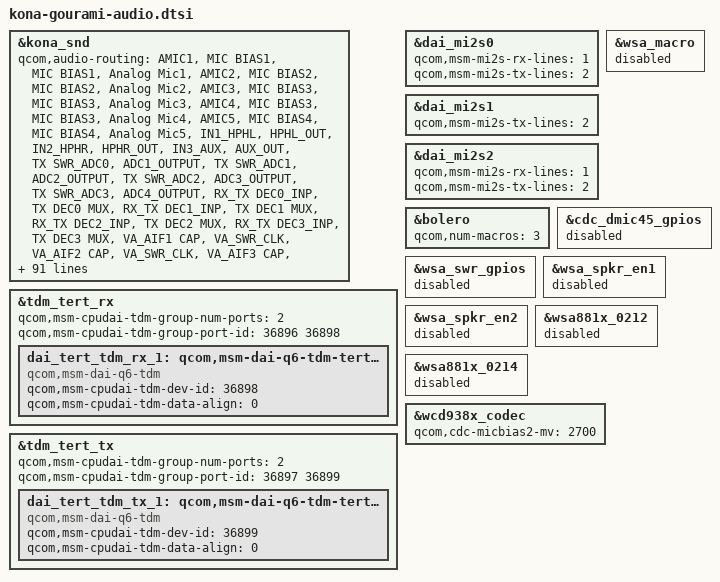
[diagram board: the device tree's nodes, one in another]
// SPDX-License-Identifier: GPL-2.0
/* Copyright (c) 2022, The Linux Foundation. All rights reserved.
 *
 * This program is free software; you can redistribute it and/or modify
 * it under the terms of the GNU General Public License version 2 and
 * only version 2 as published by the Free Software Foundation.
 *
 * This program is distributed in the hope that it will be useful,
 * but WITHOUT ANY WARRANTY; without even the implied warranty of
 * MERCHANTABILITY or FITNESS FOR A PARTICULAR PURPOSE.  See the
 * GNU General Public License for more details.
 */

#include "qcom-base/kona-audio-overlay.dtsi"

&kona_snd {
	qcom,audio-routing =
		"AMIC1", "MIC BIAS1",
		"MIC BIAS1", "Analog Mic1",
		"AMIC2", "MIC BIAS2",
		"MIC BIAS2", "Analog Mic2",
		"AMIC3", "MIC BIAS3",
		"MIC BIAS3", "Analog Mic3",
		"AMIC4", "MIC BIAS3",
		"MIC BIAS3", "Analog Mic4",
		"AMIC5", "MIC BIAS4",
		"MIC BIAS4", "Analog Mic5",
		"IN1_HPHL", "HPHL_OUT",
		"IN2_HPHR", "HPHR_OUT",
		"IN3_AUX", "AUX_OUT",
		"TX SWR_ADC0", "ADC1_OUTPUT",
		"TX SWR_ADC1", "ADC2_OUTPUT",
		"TX SWR_ADC2", "ADC3_OUTPUT",
		"TX SWR_ADC3", "ADC4_OUTPUT",
		"RX_TX DEC0_INP", "TX DEC0 MUX",
		"RX_TX DEC1_INP", "TX DEC1 MUX",
		"RX_TX DEC2_INP", "TX DEC2 MUX",
		"RX_TX DEC3_INP", "TX DEC3 MUX",
		"VA_AIF1 CAP", "VA_SWR_CLK",
		"VA_AIF2 CAP", "VA_SWR_CLK",
		"VA_AIF3 CAP", "VA_SWR_CLK",
		"VA DMIC0", "VA MIC BIAS3",
		"VA DMIC1", "VA MIC BIAS3",
		"VA DMIC2", "VA MIC BIAS1",
		"VA DMIC3", "VA MIC BIAS1",
		"VA DMIC4", "VA MIC BIAS4",
		"VA DMIC5", "VA MIC BIAS4",
		"VA SWR_ADC0", "VA_SWR_CLK",
		"VA SWR_ADC1", "VA_SWR_CLK",
		"VA SWR_ADC2", "VA_SWR_CLK",
		"VA SWR_ADC3", "VA_SWR_CLK",
		"VA SWR_MIC0", "VA_SWR_CLK",
		"VA SWR_MIC1", "VA_SWR_CLK",
		"VA SWR_MIC2", "VA_SWR_CLK",
		"VA SWR_MIC3", "VA_SWR_CLK",
		"VA SWR_MIC4", "VA_SWR_CLK",
		"VA SWR_MIC5", "VA_SWR_CLK",
		"VA SWR_MIC6", "VA_SWR_CLK",
		"VA SWR_MIC7", "VA_SWR_CLK",
		"VA SWR_ADC0", "ADC1_OUTPUT",
		"VA SWR_ADC1", "ADC2_OUTPUT",
		"VA SWR_ADC2", "ADC3_OUTPUT",
		"VA SWR_ADC3", "ADC4_OUTPUT";

	qcom,wsa-max-devs = <0>;
	qcom,msm-mbhc-usbc-audio-supported = <0>;
	/delete-property/ qcom,wsa-devs;

	asoc-cpu = <&dai_dp>, <&dai_dp1>,
			<&dai_mi2s0>, <&dai_mi2s1>,
			<&dai_mi2s2>, <&dai_mi2s3>,
			<&dai_mi2s4>, <&dai_mi2s5>, <&dai_pri_auxpcm>,
			<&dai_sec_auxpcm>, <&dai_tert_auxpcm>,
			<&dai_quat_auxpcm>, <&dai_quin_auxpcm>,
			<&dai_sen_auxpcm>,
			<&afe_pcm_rx>, <&afe_pcm_tx>, <&afe_proxy_rx>,
			<&afe_proxy_tx>, <&incall_record_rx>,
			<&incall_record_tx>, <&incall_music_rx>,
			<&incall_music_2_rx>,
			<&proxy_rx>, <&proxy_tx>,
			<&usb_audio_rx>, <&usb_audio_tx>,
			<&sb_7_rx>, <&sb_7_tx>,
			<&dai_pri_tdm_rx_0>, <&dai_pri_tdm_tx_0>,
			<&dai_sec_tdm_rx_0>, <&dai_sec_tdm_tx_0>,
			<&dai_tert_tdm_rx_0>, <&dai_tert_tdm_tx_0>,
			<&dai_tert_tdm_rx_1>, <&dai_tert_tdm_tx_1>,
			<&dai_quat_tdm_rx_0>, <&dai_quat_tdm_tx_0>,
			<&dai_quin_tdm_rx_0>, <&dai_quin_tdm_tx_0>,
			<&dai_sen_tdm_rx_0>, <&dai_sen_tdm_tx_0>,
			<&wsa_cdc_dma_0_rx>, <&wsa_cdc_dma_0_tx>,
			<&wsa_cdc_dma_1_rx>, <&wsa_cdc_dma_1_tx>,
			<&wsa_cdc_dma_2_tx>,
			<&va_cdc_dma_0_tx>, <&va_cdc_dma_1_tx>,
			<&va_cdc_dma_2_tx>,
			<&rx_cdc_dma_0_rx>, <&tx_cdc_dma_0_tx>,
			<&rx_cdc_dma_1_rx>, <&tx_cdc_dma_1_tx>,
			<&rx_cdc_dma_2_rx>, <&tx_cdc_dma_2_tx>,
			<&rx_cdc_dma_3_rx>, <&tx_cdc_dma_3_tx>,
			<&rx_cdc_dma_4_rx>, <&tx_cdc_dma_4_tx>,
			<&rx_cdc_dma_5_rx>, <&tx_cdc_dma_5_tx>,
			<&rx_cdc_dma_6_rx>, <&rx_cdc_dma_7_rx>,
			<&afe_loopback_tx>;
		asoc-cpu-names = "msm-dai-q6-dp.0", "msm-dai-q6-dp.1",
			"msm-dai-q6-mi2s.0", "msm-dai-q6-mi2s.1",
			"msm-dai-q6-mi2s.2", "msm-dai-q6-mi2s.3",
			"msm-dai-q6-mi2s.4", "msm-dai-q6-mi2s.5",
			"msm-dai-q6-auxpcm.1",
			"msm-dai-q6-auxpcm.2", "msm-dai-q6-auxpcm.3",
			"msm-dai-q6-auxpcm.4", "msm-dai-q6-auxpcm.5",
			"msm-dai-q6-auxpcm.6", "msm-dai-q6-dev.224",
			"msm-dai-q6-dev.225", "msm-dai-q6-dev.241",
			"msm-dai-q6-dev.240", "msm-dai-q6-dev.32771",
			"msm-dai-q6-dev.32772", "msm-dai-q6-dev.32773",
			"msm-dai-q6-dev.32770",
			"msm-dai-q6-dev.8194", "msm-dai-q6-dev.8195",
			"msm-dai-q6-dev.28672", "msm-dai-q6-dev.28673",
			"msm-dai-q6-dev.16398", "msm-dai-q6-dev.16399",
			"msm-dai-q6-tdm.36864", "msm-dai-q6-tdm.36865",
			"msm-dai-q6-tdm.36880", "msm-dai-q6-tdm.36881",
			"msm-dai-q6-tdm.36896", "msm-dai-q6-tdm.36897",
			"msm-dai-q6-tdm.36898", "msm-dai-q6-tdm.36899",
			"msm-dai-q6-tdm.36912", "msm-dai-q6-tdm.36913",
			"msm-dai-q6-tdm.36928", "msm-dai-q6-tdm.36929",
			"msm-dai-q6-tdm.36944", "msm-dai-q6-tdm.36945",
			"msm-dai-cdc-dma-dev.45056",
			"msm-dai-cdc-dma-dev.45057",
			"msm-dai-cdc-dma-dev.45058",
			"msm-dai-cdc-dma-dev.45059",
			"msm-dai-cdc-dma-dev.45061",
			"msm-dai-cdc-dma-dev.45089",
			"msm-dai-cdc-dma-dev.45091",
			"msm-dai-cdc-dma-dev.45093",
			"msm-dai-cdc-dma-dev.45104",
			"msm-dai-cdc-dma-dev.45105",
			"msm-dai-cdc-dma-dev.45106",
			"msm-dai-cdc-dma-dev.45107",
			"msm-dai-cdc-dma-dev.45108",
			"msm-dai-cdc-dma-dev.45109",
			"msm-dai-cdc-dma-dev.45110",
			"msm-dai-cdc-dma-dev.45111",
			"msm-dai-cdc-dma-dev.45112",
			"msm-dai-cdc-dma-dev.45113",
			"msm-dai-cdc-dma-dev.45114",
			"msm-dai-cdc-dma-dev.45115",
			"msm-dai-cdc-dma-dev.45116",
			"msm-dai-cdc-dma-dev.45118",
			"msm-dai-q6-dev.24577";
};

&tdm_tert_rx {
	qcom,msm-cpudai-tdm-group-num-ports = <2>;
	qcom,msm-cpudai-tdm-group-port-id = <36896 36898>;

    dai_tert_tdm_rx_1: qcom,msm-dai-q6-tdm-tert-rx-1 {
		compatible = "qcom,msm-dai-q6-tdm";
		qcom,msm-cpudai-tdm-dev-id = <36898>;
		qcom,msm-cpudai-tdm-data-align = <0>;
	};
};

&tdm_tert_tx {
	qcom,msm-cpudai-tdm-group-num-ports = <2>;
	qcom,msm-cpudai-tdm-group-port-id = <36897 36899>;

	dai_tert_tdm_tx_1: qcom,msm-dai-q6-tdm-tert-tx-1 {
		compatible = "qcom,msm-dai-q6-tdm";
		qcom,msm-cpudai-tdm-dev-id = <36899 >;
		qcom,msm-cpudai-tdm-data-align = <0>;
	};
};

&dai_mi2s0 {
	qcom,msm-mi2s-rx-lines = <1>;
	qcom,msm-mi2s-tx-lines = <2>;
};

&dai_mi2s1 {
	qcom,msm-mi2s-tx-lines = <2>;
};

&dai_mi2s2 {
	qcom,msm-mi2s-rx-lines = <1>;
	qcom,msm-mi2s-tx-lines = <2>;
};

&dai_mi2s2 {
	qcom,msm-mi2s-rx-lines = <1>;
	qcom,msm-mi2s-tx-lines = <2>;
};

&bolero {
	qcom,num-macros = <3>;
};

&wsa_macro {
	status = "disabled";
};

&cdc_dmic45_gpios {
	status = "disabled";
};

&wsa_swr_gpios {
	status = "disabled";
};

&wsa_spkr_en1 {
	status = "disabled";
};

&wsa_spkr_en2 {
	status = "disabled";
};

&wsa881x_0212 {
	status = "disabled";
};

&wsa881x_0214 {
	status = "disabled";
};

&wcd938x_codec {
	qcom,cdc-micbias2-mv = <2700>;
};
